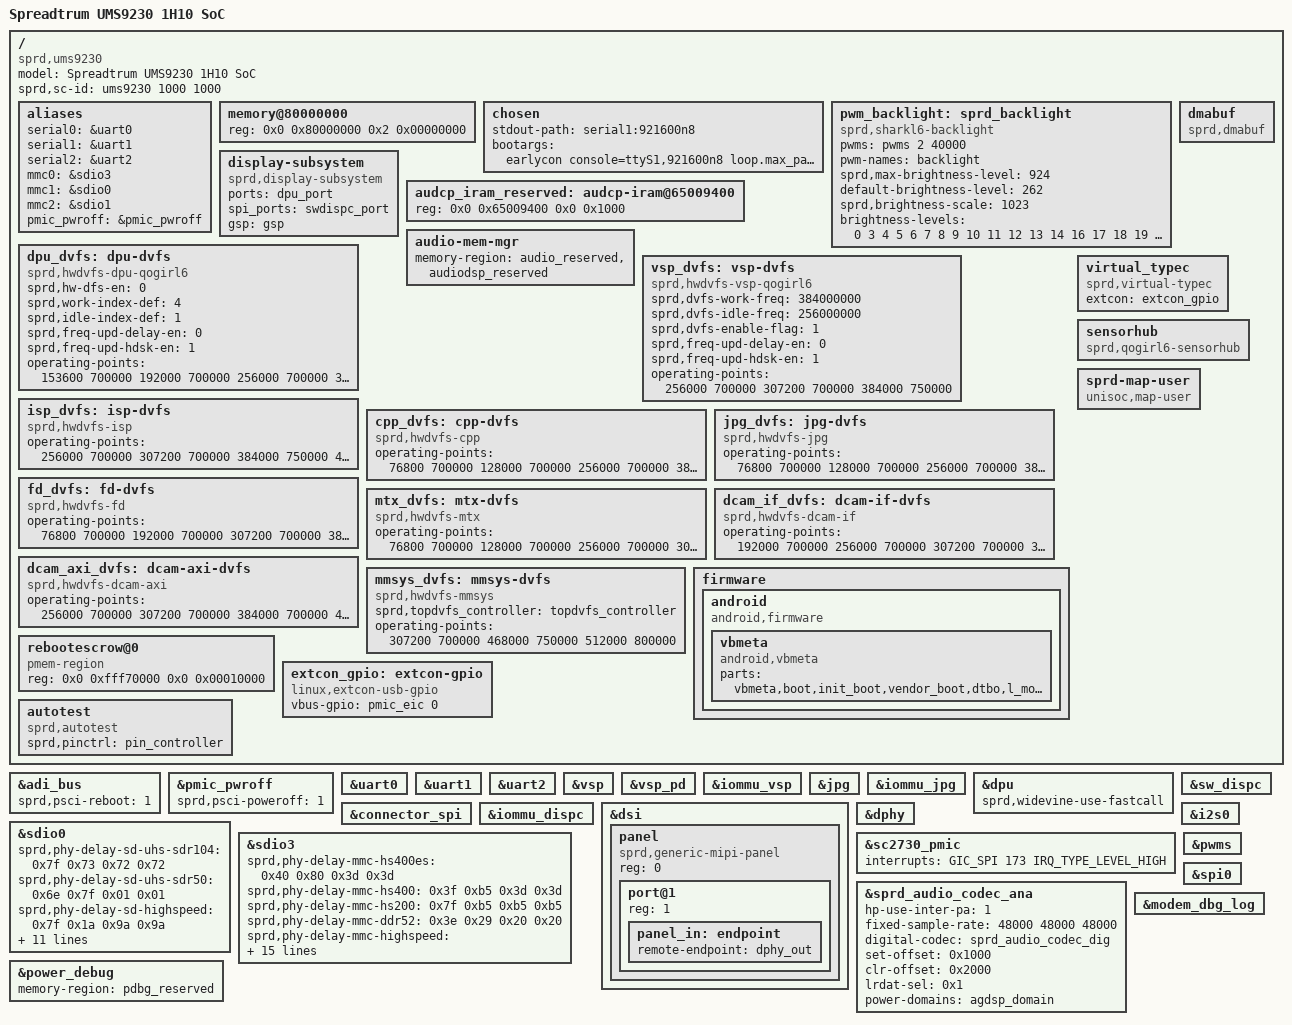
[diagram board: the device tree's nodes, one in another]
// SPDX-License-Identifier: (GPL-2.0+ OR MIT)
/*
 * Unisoc Qogirl6 platform DTS file
 *
 * Copyright (C) 2020, Unisoc Inc.
 */

/dts-v1/;

#include <dt-bindings/gpio/gpio.h>
#include "ums9230/ums9230.dtsi"
#include "sc2730/sc2730.dtsi"
#include "reserved-memory/ums9230-common.dtsi"
#include "trusty/ums9230.dtsi"
#include "battery/battery-common.dtsi"
#include "thermal/ntc-common.dtsi"
#include "sound/fe-be.dtsi"

/ {
	model = "Spreadtrum UMS9230 1H10 SoC";

	compatible = "sprd,ums9230";

	sprd,sc-id = "ums9230 1000 1000";

	aliases {
		serial0 = &uart0;
		serial1 = &uart1;
		serial2 = &uart2;
		mmc0 = &sdio3;
		mmc1 = &sdio0;
		mmc2 = &sdio1;
		pmic_pwroff = &pmic_pwroff;
	};

	memory@80000000 {
		device_type = "memory";
		reg = <0x0 0x80000000 0x2 0x00000000>;
	};

	chosen: chosen {
		stdout-path = "serial1:921600n8";
		bootargs = "earlycon console=ttyS1,921600n8
			    loop.max_part=7 loglevel=1 log_buf_len=2M kpti=0
			    firmware_class.path=/odm/firmware,/vendor/firmware
			    init=/init root=/dev/ram0 rw printk.devkmsg=on ftrace_dump_on_oops
			    swiotlb=1 dummy_hcd.num=0 rcupdate.rcu_expedited=1 rcu_nocbs=0-7";
	};

	pwm_backlight: sprd_backlight {
		compatible = "sprd,sharkl6-backlight";
		pwms = <&pwms 2 40000>;
		pwm-names = "backlight";
		sprd,max-brightness-level = <924>;
		default-brightness-level = <262>;
		sprd,brightness-scale = <1023>;
		brightness-levels = <
			  0   3   4   5   6   7
			  8   9  10  11  12  13  14  16  17  18
			 19  20  21  22  23  24  25  26  27  28
			 29  31  33  35  37  39  41  43  45  47
			 48  50  52  54  56  58  60  62  64  67
			 69  72  74  76  78  80  82  84  86  88
			 90  92  94  96  98 100 102 104 107 109
			112 114 116 118 120 122 124 126 128 130
			132 134 136 138 140 142 144 147 149 151
			154 156 158 160 162 164 166 168 170 172
			175 178 181 184 187 190 193 196 199 203
			205 208 211 214 217 220 223 226 229 234
			237 240 243 247 250 253 256 259 263 266
			269 270 274 277 280 283 287 290 294 297
			300 303 307 310 314 318 325 329 334 339
			340 343 347 350 354 358 365 369 374 380
			382 385 389 392 396 400 407 411 416 422
			426 430 434 438 442 446 452 457 460 464
			470 474 480 486 492 498 504 508 512 516
			522 527 532 536 540 545 550 555 561 568
			574 579 584 589 594 600 605 610 615 620
			625 630 635 641 647 652 657 662 667 673
			688 694 700 706 712 716 720 725 730 735
			740 746 752 758 764 770 776 782 790 798
			803 810 817 825 832 840 845 850 855 861
			866 872 878 884 890 896 903 911 918 924
		>;
	};

	dmabuf: dmabuf {
		compatible = "sprd,dmabuf";
	};

	display-subsystem {
		compatible = "sprd,display-subsystem";
		ports = <&dpu_port>;
		spi_ports = <&swdispc_port>;
		gsp = <&gsp>;
	};

	audcp_iram_reserved: audcp-iram@65009400 {
		reg = <0x0 0x65009400 0x0 0x1000>;
	};

	audio-mem-mgr {
		memory-region = <&audio_reserved &audiodsp_reserved>;
	};

	dpu_dvfs: dpu-dvfs {
		compatible = "sprd,hwdvfs-dpu-qogirl6";
		sprd,hw-dfs-en = <0>;
		sprd,work-index-def = <4>;
		sprd,idle-index-def = <1>;
		sprd,freq-upd-delay-en = <0>;
		sprd,freq-upd-hdsk-en = <1>;

		operating-points = <
				/* kHz    uV */
			153600    700000
			192000    700000
			256000    700000
			307200    700000
			384000    750000
			>;
	};

	vsp_dvfs: vsp-dvfs {
		compatible = "sprd,hwdvfs-vsp-qogirl6";
		sprd,dvfs-work-freq = <384000000>;
		sprd,dvfs-idle-freq = <256000000>;
		sprd,dvfs-enable-flag = <1>;
		sprd,freq-upd-delay-en = <0>;
		sprd,freq-upd-hdsk-en = <1>;

		operating-points = <
			/* kHz    uV */
			256000    700000
			307200    700000
			384000    750000
			>;
	};

	isp_dvfs: isp-dvfs {
		compatible = "sprd,hwdvfs-isp";
		operating-points = <
			/* kHz    uV */
			256000    700000
			307200    700000
			384000    750000
			468000    750000
			512000    800000
			>;
	};

	cpp_dvfs: cpp-dvfs {
		compatible = "sprd,hwdvfs-cpp";
		operating-points = <
			/* kHz    uV */
			76800     700000
			128000    700000
			256000    700000
			384000    750000
			>;
	};

	jpg_dvfs: jpg-dvfs {
		compatible = "sprd,hwdvfs-jpg";
		operating-points = <
			/* kHz    uV */
			76800     700000
			128000    700000
			256000    700000
			384000    750000
			>;
	};

	fd_dvfs: fd-dvfs {
		compatible = "sprd,hwdvfs-fd";
		operating-points = <
			/* kHz    uV */
			76800     700000
			192000    700000
			307200    700000
			384000    750000
			>;
	};

	mtx_dvfs: mtx-dvfs {
		compatible = "sprd,hwdvfs-mtx";
		operating-points = <
			/* kHz    uV */
			76800     700000
			128000    700000
			256000    700000
			307200    700000
			384000    750000
			468000    750000
			512000    800000
			>;
	};

	dcam_if_dvfs: dcam-if-dvfs {
		compatible = "sprd,hwdvfs-dcam-if";
		operating-points = <
			/* kHz    uV */
			192000    700000
			256000    700000
			307200    700000
			384000    700000
			468000    750000
			>;
	};

	dcam_axi_dvfs: dcam-axi-dvfs {
		compatible = "sprd,hwdvfs-dcam-axi";
		operating-points = <
			/* kHz    uV */
			256000    700000
			307200    700000
			384000    700000
			468000    750000
			>;
	};

	mmsys_dvfs: mmsys-dvfs {
			compatible = "sprd,hwdvfs-mmsys";
			sprd,topdvfs_controller = <&topdvfs_controller>;
		operating-points = <
			/* kHz    uV */
			307200    700000
			468000    750000
			512000    800000
			>;
	};

	firmware {
		android {
			compatible = "android,firmware";
			vbmeta {
				compatible = "android,vbmeta";
				parts = "vbmeta,boot,init_boot,vendor_boot,dtbo,l_modem,pm_sys,l_ldsp,l_gdsp,l_agdsp";
			};
		};
	};

	rebootescrow@0 {
		compatible = "pmem-region";
		reg = <0x0 0xfff70000 0x0 0x00010000>;
	};

	extcon_gpio: extcon-gpio {
		compatible = "linux,extcon-usb-gpio";
		vbus-gpio = <&pmic_eic 0 GPIO_ACTIVE_HIGH>;
	};

	virtual_typec: virtual_typec {
		compatible = "sprd,virtual-typec";
		extcon = <&extcon_gpio>;
		status = "okay";
	};

	sensorhub {
		compatible = "sprd,qogirl6-sensorhub", "sprd,sensor-hub";
	};

	sprd-map-user {
		compatible = "unisoc,map-user";
	};

	autotest:autotest{
		compatible = "sprd,autotest";
		sprd,pinctrl = <&pin_controller>;
	};

};

&adi_bus {
	sprd,psci-reboot = <1>;
};

&pmic_pwroff {
	sprd,psci-poweroff = <1>;
};

&uart0 {
	status = "okay";
};

&uart1 {
	status = "okay";
};

&uart2 {
	status = "okay";
};

&vsp {
	status = "okay";
};

&vsp_pd {
	status = "okay";
};

&iommu_vsp {
	status = "okay";
};

&jpg {
	status = "okay";
};

&iommu_jpg {
	status = "okay";
};

&dpu {
	/* if we need use fastcall for widevine, open the following config */
	sprd,widevine-use-fastcall;

	status = "okay";
};

&sw_dispc {
	status = "okay";
};

&connector_spi{
	status ="okay";
};

&iommu_dispc {
	status = "okay";
};

&dsi {
	status = "okay";
	#address-cells = <1>;
	#size-cells = <0>;

	panel: panel {
		compatible = "sprd,generic-mipi-panel";
		#address-cells = <1>;
		#size-cells = <0>;
		reg = <0>;

		port@1 {
			reg = <1>;
			panel_in: endpoint {
				remote-endpoint = <&dphy_out>;
			};
		};
	};
};

&dphy {
	status = "okay";
};

&i2s0 {
	status = "okay";
};

&sdio0 {
	sprd,phy-delay-sd-uhs-sdr104 = <0x7f 0x73 0x72 0x72>;
	sprd,phy-delay-sd-uhs-sdr50 = <0x6e 0x7f 0x01 0x01>;
	sprd,phy-delay-sd-highspeed = <0x7f 0x1a 0x9a 0x9a>;
	sprd,phy-delay-legacy = <0x7f 0x1a 0x9a 0x9a>;
	vmmc-supply = <&vddsdcore>;
	vqmmc-supply = <&vddsdio>;
	voltage-ranges = <3000 3000>;
	bus-width = <4>;
	sd-uhs-sdr104;
	sd-uhs-sdr50;
	sprd,name = "sdio_sd";
	sprd,sdio-adma;
	no-sdio;
	no-mmc;
	status = "okay";
};

&sdio3 {
	sprd,phy-delay-mmc-hs400es = <0x40 0x80 0x3d 0x3d>;
	sprd,phy-delay-mmc-hs400 = <0x3f 0xb5 0x3d 0x3d>;
	sprd,phy-delay-mmc-hs200 = <0x7f 0xb5 0xb5 0xb5>;
	sprd,phy-delay-mmc-ddr52 = <0x3e 0x29 0x20 0x20>;
	sprd,phy-delay-mmc-highspeed = <0x60 0x2e 0x2c 0x2c>;
	vmmc-supply = <&vddemmccore>;
	voltage-ranges = <3000 3000>;
	bus-width = <8>;
	non-removable;
	cap-mmc-hw-reset;
	mmc-hs400-enhanced-strobe;
	mmc-hs400-1_8v;
	mmc-hs200-1_8v;
	mmc-ddr-1_8v;
	sprd,name = "sdio_emmc";
	sprd,sdio-adma;
	no-sdio;
	no-sd;
	status = "okay";
	supports-swcq;
};

&sc2730_pmic {
	interrupts = <GIC_SPI 173 IRQ_TYPE_LEVEL_HIGH>;
};

&pwms {
	status = "okay";
};

&sprd_audio_codec_ana {
	status = "okay";
	hp-use-inter-pa = <1>;
	fixed-sample-rate = <48000 48000 48000>;
	digital-codec = <&sprd_audio_codec_dig>;
	set-offset = <0x1000>;
	clr-offset = <0x2000>;
	lrdat-sel = <0x1>;
	power-domains = <&agdsp_domain>;
};

&spi0 {
	/*used for fingerprint sensor*/
	status = "okay";
};

&power_debug {
	status = "okay";
	memory-region = <&pdbg_reserved>;
};

&modem_dbg_log{
	status = "okay";
};
